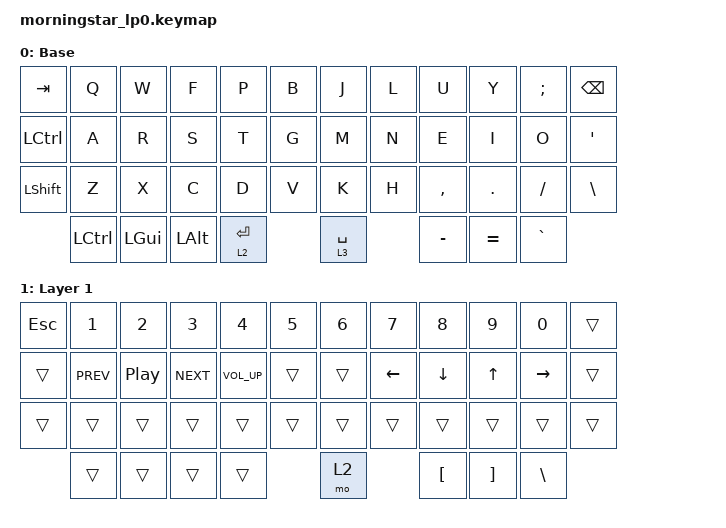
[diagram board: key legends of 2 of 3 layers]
#include <behaviors.dtsi>
#include <dt-bindings/zmk/keys.h>
#include <dt-bindings/zmk/bt.h>
#include <dt-bindings/zmk/outputs.h>
#include <dt-bindings/zmk/ext_power.h>

/ {
    keymap {
        compatible = "zmk,keymap";

        default_layer {
            display-name = "Base";
            bindings = <
                &kp TAB   &kp Q     &kp W     &kp F     &kp P     &kp B     &kp J     &kp L     &kp U     &kp Y     &kp SEMI  &kp BSPC 
                &kp LCTRL &kp A     &kp R     &kp S     &kp T     &kp G     &kp M     &kp N     &kp E     &kp I     &kp O     &kp APOS
                &kp LSHFT &kp Z     &kp X     &kp C     &kp D     &kp V     &kp K     &kp H     &kp COMMA &kp DOT   &kp FSLH  &kp BSLH 
                          &kp LCTRL &kp LGUI  &kp LALT  &lt 2 RET           &lt 3 SPACE         &kp MINUS &kp EQUAL &kp GRAVE
            >;
        };

        1 {
            display-name = "Layer 1";
            bindings = <
                &kp ESC   &kp N1      &kp N2   &kp N3     &kp N4       &kp N5    &kp N6    &kp N7    &kp N8    &kp N9    &kp N0  &trans
                &trans    &kp C_PREV  &kp C_PP &kp C_NEXT &kp C_VOL_UP &trans    &trans    &kp LEFT  &kp DOWN  &kp UP    &kp RIGHT &trans
                &trans    &trans      &trans   &trans     &trans       &trans    &trans    &trans    &trans    &trans    &trans    &trans
                          &trans      &trans   &trans     &trans                   &mo 2             &kp LBKT  &kp RBKT  &kp BSLH      
           >;
        };

       2 {
           display-name = "Layer 2";
           bindings = <
               &bt BT_CLR &bt BT_SEL 0 &bt BT_SEL 1 &bt BT_SEL 2 &bt BT_SEL 3 &bt BT_SEL 4 &trans &trans &trans &trans   &trans    &trans
               &trans     &trans       &trans       &trans       &trans       &trans       &trans &trans &trans &trans   &trans    &reset
               &trans     &trans       &trans       &trans       &trans       &trans       &trans &trans &trans &trans   &trans    &bootloader
                          &trans       &out OUT_USB &out OUT_BLE &trans                    &trans        &trans &trans   &trans    &none 
             >;
       };
    };
};

// --------------------------------------------------------------------------------------------------------------------------
// |   TAB   |    Q    |    W    |    F    |    P    |    B    |    J    |    L    |    U    |    Y    |   SEMI  |   BSPC   |
// |  LCTRL  |    A    |    R    |    S    |    T    |    G    |    M    |    N    |    E    |    I    |    O    |   APOS   |
// |  LSHFT  |    Z    |    X    |    C    |    D    |    V    |    K    |    H    |  COMMA  |   DOT   |   FSLH  |   GRAVE  |
// |         |  LCTRL  |  LGUI   |   LALT  |  1/RET  |         | 1/SPACE |         |  MINUS  |  EQUAL  |   BSLH  |   

// NO YES YES YES YES NO | YES NO YES YES YES NO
